# TC35680 register map
Vendor: Toshiba Electronic Devices and Storage Corporation; File version: 0.1
CPU: CM0 r0p0, little endian, no MPU, no FPU, 4 interrupt priority bits
Registers are 32-bit, read-write, no defined reset value unless marked. A register's access mark holds for its fields unless they carry their own. Offsets are from the block's base; lines under a group give offsets from that group; [hi:lo] are bit positions; {n}, {i} and the like mark numbered series; 'fields as' and 'values as' point back to an identical list; <NAME> marks a mode.

## Memory map
0x40001000 DMAC size 0x200
0x40040240 BluetoothCounter size 0x100
0x40044000 UART1 size 0x40
0x40046000 SPI1 size 0x30 — Serial Peripheral Interface(Master/Slave)
0x40048000 I2C1 size 0x30
0x4004A000 GPADC size 0x20 — General Purpose ADC registers
0x4004A100 PWM size 0x500 — Pulse Width Modulation
0x4004C000 CLOCK size 0x100 — Clock Supply for SPI and PWM
0x4004D000 TimerBCG size 0x200 — Timer (BCTimer, GTimer)
0x4004E000 GPIO size 0x500 — General Purpose Input/Output
0x40055000 PMU size 0x200 — Power Management Unit
0x40056000 SPI2 size 0x30 — Serial Peripheral Interface(Master/Slave)
0x40058000 I2C2 size 0x30 — I2C1
0x4005C000 UART2 size 0x40 — UART1

## UART1
Base 0x40044000
Same registers: UART2 0x4005C000
0x00 UART_RBR_THR — Receiver Buffer Register/Transmitter Holding Register
  [7:0] RBR_THR — Tx/Rx Data
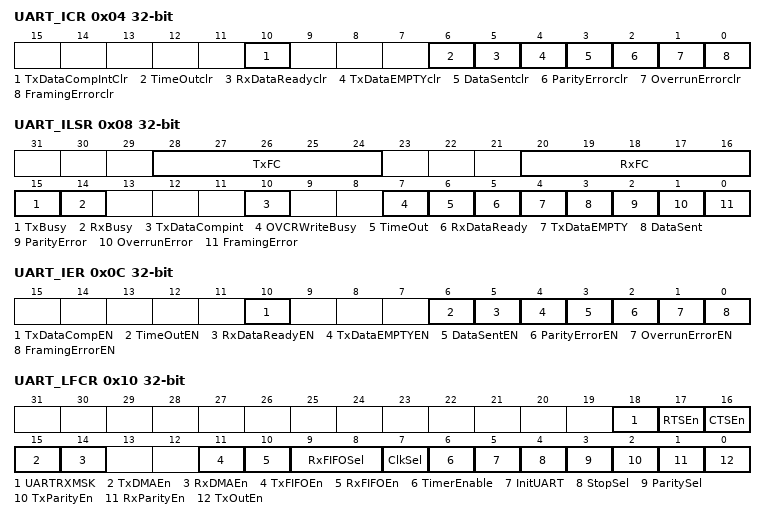
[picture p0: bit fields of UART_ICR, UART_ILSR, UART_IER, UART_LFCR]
0x04 UART_ICR — Interrupt Clear Register
  [10] TxDataCompIntClr — Clear TxDataComp Interrupt
  [6] TimeOutclr — Clear CWT Time Out Interrupt
  [5] RxDataReadyclr — Clear RxDataReady Interrupt
  [4] TxDataEMPTYclr — Clear TxDataEMPTY Interrupt
  [3] DataSentclr — Clear DataSent Interrupt
  [2] ParityErrorclr — Clear ParityError Interrupt
  [1] OverrunErrorclr — Clear OverrunError Interrupt
  [0] FramingErrorclr — Clear Framing Error Interrupt
0x08 UART_ILSR — Interrupt and Line Status Register
  [28:24] TxFC — Count in Tx FIFO
  [20:16] RxFC — Count in Rx FIFO
  [15] TxBusy — Indicates is Tx working
  [14] RxBusy — Indicates if Rx working
  [10] TxDataCompint — Tx Data Complete Interrupt
  [7] OVCRWriteBusy — Status of OVCR Write
  [6] TimeOut — CWT TimeOut Interrupt Status
  [5] RxDataReady — RxDataReady Interupt Status
  [4] TxDataEMPTY — TxDataEMPTY Interrupt Status
  [3] DataSent — Data Sent Interrupt Status
  [2] ParityError — ParityErrorr Interrupt Status
  [1] OverrunError — OverrunError Interrupt Status
  [0] FramingError — FramingError Interrupt Status
0x0C UART_IER — Interrupt Enable Register
  [10] TxDataCompEN — TxDataComp Interrupt Enable
  [6] TimeOutEN — CWT TimeOut Interrupt Enable
  [5] RxDataReadyEN — RxDataReady Interrupt Enable
  [4] TxDataEMPTYEN — TxDataEMPTY Interrupt Enable
  [3] DataSentEN — DataSent Interrupt Enable
  [2] ParityErrorEN — ParityError Interrupt Enable
  [1] OverrunErrorEN — OverrunError Interrupt Enable
  [0] FramingErrorEN — FramingError Interrupt Enable
0x10 UART_LFCR — Line and FIFO Control Register
  [18] UARTRXMSK — Rx Data Mask
  [17] RTSEn — Enable RTS Flow Control
  [16] CTSEn — Enable CTS Flow Control
  [15] TxDMAEn — TxDMA Request output enable
  [14] RxDMAEn — RxDMA Request output enable
  [11] TxFIFOEn — TxFIFO Enable/Disable
  [10] RxFIFOEn — RxFIFO Enable/Disable
  [9:8] RxFIFOSel — Select Rx FIFO Watermark Level
  [7] ClkSel — Select Clock for BaudRate
  [6] TimerEnable — Tx Timer Enable/Disable
  [5] InitUART — Initialize Sample Counter
  [4] StopSel — Select Stop bit(1bit or 2bit)
  [3] ParitySel — Select Parity bit (odd or even)
  [2] TxParityEn — Tx Data parity enable/disable
  [1] RxParityEn — Rx Data parity enable/disable
  [0] TxOutEn — Tx Output enable/disable
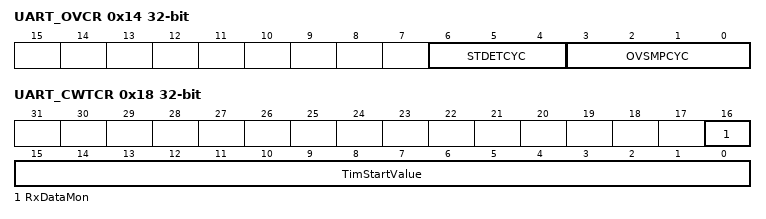
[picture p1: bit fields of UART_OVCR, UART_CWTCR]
0x14 UART_OVCR — Sampling Control Register
  [6:4] STDETCYC — Start bit detect cycles for UART Rx Data
  [3:0] OVSMPCYC — Oversample cycles setting
0x18 UART_CWTCR — CWT Control Register
  [16] RxDataMon — Monitor data existance info after Character Inteval Timeout
  [15:0] TimStartValue — UART Receive Timer value
0x1C UART_IBRD — Baud Rate Setting Register
  [15:0] BAUDINT — UART Baudrate Integer divisor value
0x30 UART_FBRD — Baud Rate Decimal Setting Register
  [5:0] UFBRD — UART Baudrate Decimal Setting
